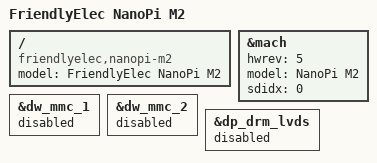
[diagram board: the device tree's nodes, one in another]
/*
 * (C) Copyright 2017 FriendlyElec Computer Tech. Co., Ltd.
 * (http://www.friendlyarm.com)
 *
 * This program is free software; you can redistribute it and/or
 * modify it under the terms of the GNU General Public License
 * as published by the Free Software Foundation; either version 2
 * of the License, or (at your option) any later version.
 *
 * This program is distributed in the hope that it will be useful,
 * but WITHOUT ANY WARRANTY; without even the implied warranty of
 * MERCHANTABILITY or FITNESS FOR A PARTICULAR PURPOSE.  See the
 * GNU General Public License for more details.
 *
 * You should have received a copy of the GNU General Public License
 * along with this program.  If not, see <http://www.gnu.org/licenses/>.
 */

/dts-v1/;
#include "s5p4418-nanopi2-common.dtsi"

/ {
	model = "FriendlyElec NanoPi M2";
	compatible = "friendlyelec,nanopi-m2", "nexell,s5p4418";

	/delete-node/ wlan;
	/delete-node/ bt_bcm;
};

&mach {
	hwrev = <5>;
	model = "NanoPi M2";
	sdidx = <0>;
};

&dw_mmc_1 {
	status = "disabled";
};

&dw_mmc_2 {
	status = "disabled";
};

&dp_drm_lvds{
	status = "disabled";
};
